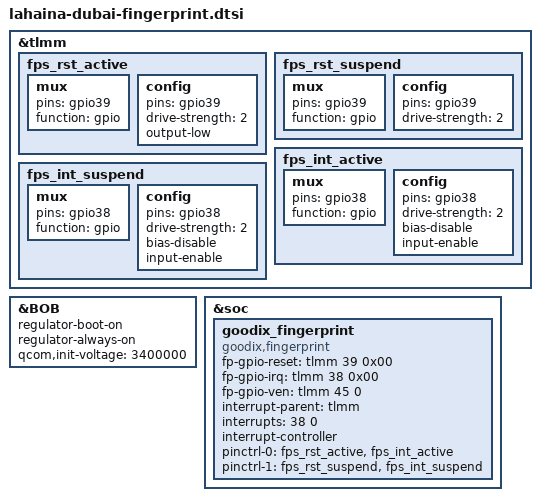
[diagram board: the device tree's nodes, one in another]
/* Copyright (c) 2020, The Linux Foundation. All rights reserved.
 *
 * This program is free software; you can redistribute it and/or modify
 * it under the terms of the GNU General Public License version 2 and
 * only version 2 as published by the Free Software Foundation.
 *
 * This program is distributed in the hope that it will be useful,
 * but WITHOUT ANY WARRANTY; without even the implied warranty of
 * MERCHANTABILITY or FITNESS FOR A PARTICULAR PURPOSE.  See the
 * GNU General Public License for more details.
 */

&tlmm {
	fps_rst_active: fps_rst_active {
		/* active state */
		mux {
			pins = "gpio39";
			function = "gpio";
		};

		config {
			pins = "gpio39";
			drive-strength = <2>; /* 2 MA */
			output-low;
		};
	};

	fps_rst_suspend: fps_rst_suspend {
		/* sleep state */
		mux {
			pins = "gpio39";
			function = "gpio";
		};

		config {
			pins = "gpio39";
			drive-strength = <2>; /* 2 MA */
		};
	};

	fps_int_active: fps_int_active {
		/* active state */
		mux {
			pins = "gpio38";
			function = "gpio";
		};

		config {
			pins = "gpio38";
			drive-strength = <2>; /* 2 MA */
			bias-disable;
			input-enable;
		};
	};

	fps_int_suspend: fps_int_suspend {
		/* sleep state */
		mux {
			pins = "gpio38";
			function = "gpio";
		};

		config {
			pins = "gpio38";
			drive-strength = <2>; /* 2 MA */
			bias-disable;
			input-enable;
		};
	};
};

&BOB {
	regulator-boot-on;
	regulator-always-on;
	qcom,init-voltage = <3400000>;
	status = "ok";
};

&soc {
	goodix_fingerprint{
		compatible = "goodix,fingerprint";
		fp-gpio-reset = <&tlmm 39 0x00>;
		fp-gpio-irq = <&tlmm 38 0x00>;
		fp-gpio-ven = <&tlmm 45 0>;
		interrupt-parent = <&tlmm>;
		interrupts = <38 0>;
		interrupt-controller;
		pinctrl-names = "default", "suspend";
		pinctrl-0 = <&fps_rst_active &fps_int_active>;
		pinctrl-1 = <&fps_rst_suspend &fps_int_suspend>;
	};
};
